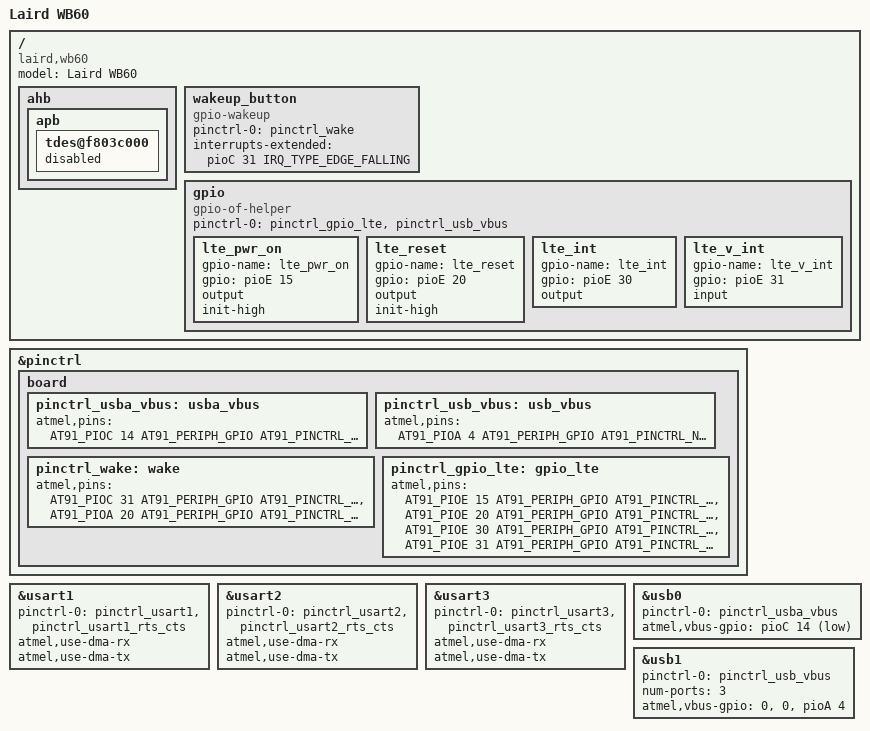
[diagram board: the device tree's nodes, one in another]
// SPDX-License-Identifier: GPL-2.0
/*
 * at91-wb60.dts - Device Tree file for the WB60 module
 *
 *  Copyright (C) 2020 Laird Connectivity,
 *		  2020 Boris Krasnovskiy <boris.krasnovskiy@lairdconnect.com>
 *
 * Licensed under GPLv2 or later.
 */

/ {
	model = "Laird WB60";
	compatible = "laird,wb60", "laird,som60", "atmel,sama5d36", "atmel,sama5d3", "atmel,sama5";

	ahb {
		apb {
			tdes@f803c000 {
				// Disabled due shortage of DMA channels
				status = "disabled";
			};
		};
	};

	wakeup_button {
		pinctrl-names = "default";
		pinctrl-0 = <&pinctrl_wake>;

		compatible = "gpio-wakeup";

		interrupts-extended = <&pioC 31 IRQ_TYPE_EDGE_FALLING>;
			//<&pioA 20 IRQ_TYPE_EDGE_FALLING>;
	};

	gpio {
		compatible = "gpio-of-helper";
		status = "okay";
		pinctrl-names = "default";
		pinctrl-0 = <&pinctrl_gpio_lte &pinctrl_usb_vbus>;

		lte_pwr_on {
			gpio-name = "lte_pwr_on";
			gpio = <&pioE 15 GPIO_ACTIVE_HIGH>;
			output;
			init-high;
		};

		lte_reset {
			gpio-name = "lte_reset";
			gpio = <&pioE 20 GPIO_ACTIVE_HIGH>;
			output;
			init-high;
		};

		lte_int {
			gpio-name = "lte_int";
			gpio = <&pioE 30 GPIO_ACTIVE_HIGH>;
			output;
		};

		lte_v_int {
			gpio-name = "lte_v_int";
			gpio = <&pioE 31 GPIO_ACTIVE_HIGH>;
			input;
		};
	};
};

&pinctrl {
	board {
		pinctrl_usba_vbus: usba_vbus {
			atmel,pins =
				<AT91_PIOC 14 AT91_PERIPH_GPIO AT91_PINCTRL_DEGLITCH>;
		};

		pinctrl_usb_vbus: usb_vbus {
			atmel,pins =
				<AT91_PIOA 4 AT91_PERIPH_GPIO AT91_PINCTRL_NONE>;
		};

		pinctrl_wake: wake {
			atmel,pins =
				<AT91_PIOC 31 AT91_PERIPH_GPIO AT91_PINCTRL_PULL_UP_DEGLITCH>,
				<AT91_PIOA 20 AT91_PERIPH_GPIO AT91_PINCTRL_PULL_UP_DEGLITCH>;
		};

		pinctrl_gpio_lte: gpio_lte {
		   atmel,pins =
				<AT91_PIOE 15 AT91_PERIPH_GPIO AT91_PINCTRL_MULTI_DRIVE>,
				<AT91_PIOE 20 AT91_PERIPH_GPIO AT91_PINCTRL_MULTI_DRIVE>,
				<AT91_PIOE 30 AT91_PERIPH_GPIO AT91_PINCTRL_NONE>,
				<AT91_PIOE 31 AT91_PERIPH_GPIO AT91_PINCTRL_NONE>;
		};
	};
};

&usart1 {
	pinctrl-0 = <&pinctrl_usart1 &pinctrl_usart1_rts_cts>;

	atmel,use-dma-rx;
	atmel,use-dma-tx;

	status = "okay";
};

&usart2 {
	pinctrl-0 = <&pinctrl_usart2 &pinctrl_usart2_rts_cts>;

	atmel,use-dma-rx;
	atmel,use-dma-tx;

	status = "okay";
};

&usart3 {
	pinctrl-0 = <&pinctrl_usart3 &pinctrl_usart3_rts_cts>;

	atmel,use-dma-rx;
	atmel,use-dma-tx;

	status = "okay";
};

&usb0 {
	pinctrl-names = "default";
	pinctrl-0 = <&pinctrl_usba_vbus>;

	atmel,vbus-gpio = <&pioC 14 GPIO_ACTIVE_LOW>;

	status = "okay";
};

&usb1 {
	pinctrl-names = "default";
	pinctrl-0 = <&pinctrl_usb_vbus>;

	num-ports = <3>;
	atmel,vbus-gpio = <0>, <0>, <&pioA 4 GPIO_ACTIVE_HIGH>;
};
